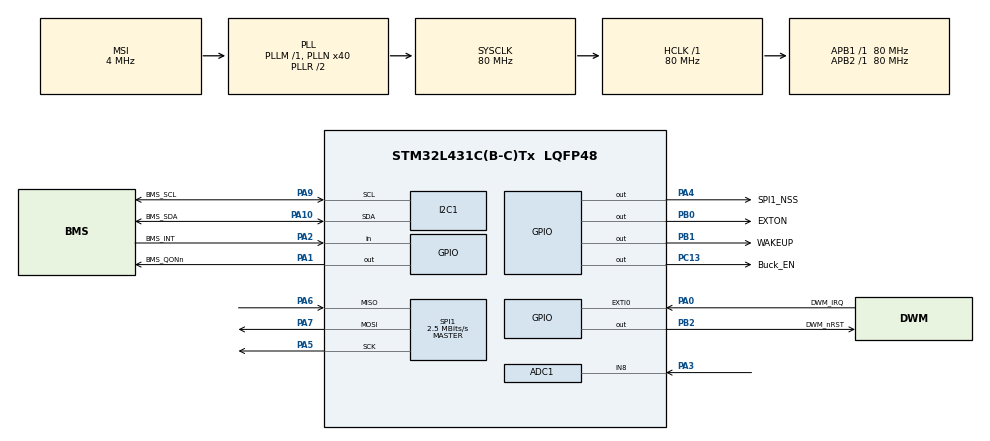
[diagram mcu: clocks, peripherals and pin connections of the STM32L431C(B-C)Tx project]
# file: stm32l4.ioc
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ADC1.Channel-0\#ChannelRegularConversion=ADC_CHANNEL_8
ADC1.NbrOfConversionFlag=1
ADC1.OffsetNumber-0\#ChannelRegularConversion=ADC_OFFSET_NONE
ADC1.Rank-0\#ChannelRegularConversion=1
ADC1.SamplingTime-0\#ChannelRegularConversion=ADC_SAMPLETIME_2CYCLES_5
ADC1.master=1
I2C1.Timing=0x10D19CE4
Mcu.Family=STM32L4
Mcu.Name=STM32L431C(B-C)Tx
Mcu.Package=LQFP48
NVIC.EXTI0_IRQn=true\:0\:0\:false\:false\:true\:true\:true\:true
NVIC.PriorityGroup=NVIC_PRIORITYGROUP_4
PA0.GPIO_Label=DWM_IRQ
PA0.Signal=GPXTI0
PA1.GPIO_Label=BMS_QONn
PA1.Signal=GPIO_Output
PA10.GPIO_Label=BMS_SDA
PA10.Mode=I2C
PA10.Signal=I2C1_SDA
PA13\ (JTMS-SWDIO).Mode=Trace_Asynchronous_SW
PA13\ (JTMS-SWDIO).Signal=SYS_JTMS-SWDIO
PA14\ (JTCK-SWCLK).Mode=Trace_Asynchronous_SW
PA14\ (JTCK-SWCLK).Signal=SYS_JTCK-SWCLK
PA2.GPIO_Label=BMS_INT
PA2.Signal=GPIO_Input
PA3.Signal=ADCx_IN8
PA4.GPIO_Label=SPI1_NSS
PA4.GPIO_PuPd=GPIO_PULLUP
PA4.GPIO_Speed=GPIO_SPEED_FREQ_MEDIUM
PA4.Signal=GPIO_Output
PA5.Mode=Full_Duplex_Master
PA5.Signal=SPI1_SCK
PA6.Mode=Full_Duplex_Master
PA6.Signal=SPI1_MISO
PA7.Mode=Full_Duplex_Master
PA7.Signal=SPI1_MOSI
PA9.GPIO_Label=BMS_SCL
PA9.Mode=I2C
PA9.Signal=I2C1_SCL
PB0.GPIO_Label=EXTON
PB0.Signal=GPIO_Output
PB1.GPIO_Label=WAKEUP
PB1.GPIO_Speed=GPIO_SPEED_FREQ_MEDIUM
PB1.Signal=GPIO_Output
PB2.GPIO_Label=DWM_nRST
PB2.PinState=GPIO_PIN_SET
PB2.Signal=GPIO_Output
PB3\ (JTDO-TRACESWO).Mode=Trace_Asynchronous_SW
PB3\ (JTDO-TRACESWO).Signal=SYS_JTDO-SWO
PC13.GPIO_Label=Buck_EN
PC13.Signal=GPIO_Output
PC14-OSC32_IN\ (PC14).Mode=LSE-External-Oscillator
PC14-OSC32_IN\ (PC14).Signal=RCC_OSC32_IN
PC15-OSC32_OUT\ (PC15).Mode=LSE-External-Oscillator
PC15-OSC32_OUT\ (PC15).Signal=RCC_OSC32_OUT
PH0-OSC_IN\ (PH0).Mode=HSE-External-Oscillator
PH0-OSC_IN\ (PH0).Signal=RCC_OSC_IN
PH1-OSC_OUT\ (PH1).Mode=HSE-External-Oscillator
PH1-OSC_OUT\ (PH1).Signal=RCC_OSC_OUT
ProjectManager.HeapSize=0x200
ProjectManager.StackSize=0x400
ProjectManager.TargetToolchain=CMake
RCC.ADCFreq_Value=32000000
RCC.AHBFreq_Value=80000000
RCC.APB1Freq_Value=80000000
RCC.APB1TimFreq_Value=80000000
RCC.APB2Freq_Value=80000000
RCC.APB2TimFreq_Value=80000000
RCC.CortexFreq_Value=80000000
RCC.HCLKFreq_Value=80000000
RCC.HSE_VALUE=8000000
RCC.HSI48_VALUE=48000000
RCC.HSI_VALUE=16000000
RCC.MSI_VALUE=4000000
RCC.PLLN=40
RCC.PLLSAI1N=16
RCC.SYSCLKFreq_VALUE=80000000
RCC.SYSCLKSource=RCC_SYSCLKSOURCE_PLLCLK
RCC.VCOOutputFreq_Value=160000000
SH.ADCx_IN8.0=ADC1_IN8,IN8-Single-Ended
SPI1.BaudRatePrescaler=SPI_BAUDRATEPRESCALER_32
SPI1.CalculateBaudRate=2.5 MBits/s
SPI1.DataSize=SPI_DATASIZE_8BIT
SPI1.Direction=SPI_DIRECTION_2LINES
SPI1.Mode=SPI_MODE_MASTER
SPI1.VirtualType=VM_MASTER
board=custom

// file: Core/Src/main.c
/* USER CODE BEGIN Header */
/**
 ******************************************************************************
 * @file           : main.c
 * @brief          : Main program body
 ******************************************************************************
 * @attention
 *
 * Copyright (c) 2026 STMicroelectronics.
 * All rights reserved.
 *
 * This software is licensed under terms that can be found in the LICENSE file
 * in the root directory of this software component.
 * If no LICENSE file comes with this software, it is provided AS-IS.
 *
 ******************************************************************************
 */
/* USER CODE END Header */
#include "main.h"

/* USER CODE BEGIN Includes */
#include "communication.h"
#include "deca_device_api.h"
#include "deca_interface.h"
#include "dw3000_config.h"
#include "port.h"
#include <stdint.h>

/* USER CODE END Includes */

ADC_HandleTypeDef hadc1;

I2C_HandleTypeDef hi2c1;

SPI_HandleTypeDef hspi1;

void SystemClock_Config(void);
static void MX_GPIO_Init(void);
static void MX_SPI1_Init(void);
static void MX_ADC1_Init(void);
static void MX_I2C1_Init(void);
/* USER CODE BEGIN PFP */
void init_SPI()
{
    MX_SPI1_Init();
}
/* USER CODE END PFP */

int main(void)
{

    /* MCU Configuration--------------------------------------------------------*/

    /* Reset of all peripherals, Initializes the Flash interface and the Systick. */
    HAL_Init();

    /* Configure the system clock */
    SystemClock_Config();

    /* Initialize all configured peripherals */
    MX_GPIO_Init();
    MX_SPI1_Init();
    MX_ADC1_Init();
    MX_I2C1_Init();
    /* USER CODE BEGIN 2 */
    HAL_GPIO_WritePin(SPI1_NSS_GPIO_Port, SPI1_NSS_Pin, GPIO_PIN_RESET);
    dwm300_initialize();

    /* USER CODE END 2 */

    /* Infinite loop */
    while (1)
    {
        static uint8_t msg[] = {'t', 'e', 's', 't', ' ', 'm', 'e', 's', 's', 'a', 'g', 'e', '!'};
        send_msg_polling(msg);

        HAL_Delay(100000000000);
        static uint8_t rec[sizeof(msg)];
        recieve_msg_polling(rec);
    }
}

void SystemClock_Config(void)
{
    RCC_OscInitTypeDef RCC_OscInitStruct = {0};
    RCC_ClkInitTypeDef RCC_ClkInitStruct = {0};

    /** Configure the main internal regulator output voltage
     */
    if (HAL_PWREx_ControlVoltageScaling(PWR_REGULATOR_VOLTAGE_SCALE1) != HAL_OK)
    {
        Error_Handler();
    }

    /** Configure LSE Drive Capability
     */
    HAL_PWR_EnableBkUpAccess();
    __HAL_RCC_LSEDRIVE_CONFIG(RCC_LSEDRIVE_LOW);

    /** Initializes the RCC Oscillators according to the specified parameters
     * in the RCC_OscInitTypeDef structure.
     */
    RCC_OscInitStruct.OscillatorType = RCC_OSCILLATORTYPE_LSE | RCC_OSCILLATORTYPE_MSI;
    RCC_OscInitStruct.LSEState = RCC_LSE_ON;
    RCC_OscInitStruct.MSIState = RCC_MSI_ON;
    RCC_OscInitStruct.MSICalibrationValue = 0;
    RCC_OscInitStruct.MSIClockRange = RCC_MSIRANGE_6;
    RCC_OscInitStruct.PLL.PLLState = RCC_PLL_ON;
    RCC_OscInitStruct.PLL.PLLSource = RCC_PLLSOURCE_MSI;
    RCC_OscInitStruct.PLL.PLLM = 1;
    RCC_OscInitStruct.PLL.PLLN = 40;
    RCC_OscInitStruct.PLL.PLLP = RCC_PLLP_DIV7;
    RCC_OscInitStruct.PLL.PLLQ = RCC_PLLQ_DIV2;
    RCC_OscInitStruct.PLL.PLLR = RCC_PLLR_DIV2;
    if (HAL_RCC_OscConfig(&RCC_OscInitStruct) != HAL_OK)
    {
        Error_Handler();
    }

    /** Initializes the CPU, AHB and APB buses clocks
     */
    RCC_ClkInitStruct.ClockType = RCC_CLOCKTYPE_HCLK | RCC_CLOCKTYPE_SYSCLK | RCC_CLOCKTYPE_PCLK1 | RCC_CLOCKTYPE_PCLK2;
    RCC_ClkInitStruct.SYSCLKSource = RCC_SYSCLKSOURCE_PLLCLK;
    RCC_ClkInitStruct.AHBCLKDivider = RCC_SYSCLK_DIV1;
    RCC_ClkInitStruct.APB1CLKDivider = RCC_HCLK_DIV1;
    RCC_ClkInitStruct.APB2CLKDivider = RCC_HCLK_DIV1;

    if (HAL_RCC_ClockConfig(&RCC_ClkInitStruct, FLASH_LATENCY_4) != HAL_OK)
    {
        Error_Handler();
    }

    /** Enable MSI Auto calibration
     */
    HAL_RCCEx_EnableMSIPLLMode();
}

static void MX_ADC1_Init(void)
{

    ADC_ChannelConfTypeDef sConfig = {0};

    /** Common config
     */
    hadc1.Instance = ADC1;
    hadc1.Init.ClockPrescaler = ADC_CLOCK_ASYNC_DIV1;
    hadc1.Init.Resolution = ADC_RESOLUTION_12B;
    hadc1.Init.DataAlign = ADC_DATAALIGN_RIGHT;
    hadc1.Init.ScanConvMode = ADC_SCAN_DISABLE;
    hadc1.Init.EOCSelection = ADC_EOC_SINGLE_CONV;
    hadc1.Init.LowPowerAutoWait = DISABLE;
    hadc1.Init.ContinuousConvMode = DISABLE;
    hadc1.Init.NbrOfConversion = 1;
    hadc1.Init.DiscontinuousConvMode = DISABLE;
    hadc1.Init.ExternalTrigConv = ADC_SOFTWARE_START;
    hadc1.Init.ExternalTrigConvEdge = ADC_EXTERNALTRIGCONVEDGE_NONE;
    hadc1.Init.DMAContinuousRequests = DISABLE;
    hadc1.Init.Overrun = ADC_OVR_DATA_PRESERVED;
    hadc1.Init.OversamplingMode = DISABLE;
    if (HAL_ADC_Init(&hadc1) != HAL_OK)
    {
        Error_Handler();
    }

    /** Configure Regular Channel
     */
    sConfig.Channel = ADC_CHANNEL_8;
    sConfig.Rank = ADC_REGULAR_RANK_1;
    sConfig.SamplingTime = ADC_SAMPLETIME_2CYCLES_5;
    sConfig.SingleDiff = ADC_SINGLE_ENDED;
    sConfig.OffsetNumber = ADC_OFFSET_NONE;
    sConfig.Offset = 0;
    if (HAL_ADC_ConfigChannel(&hadc1, &sConfig) != HAL_OK)
    {
        Error_Handler();
    }
}

static void MX_I2C1_Init(void)
{

    hi2c1.Instance = I2C1;
    hi2c1.Init.Timing = 0x10D19CE4;
    hi2c1.Init.OwnAddress1 = 0;
    hi2c1.Init.AddressingMode = I2C_ADDRESSINGMODE_7BIT;
    hi2c1.Init.DualAddressMode = I2C_DUALADDRESS_DISABLE;
    hi2c1.Init.OwnAddress2 = 0;
    hi2c1.Init.OwnAddress2Masks = I2C_OA2_NOMASK;
    hi2c1.Init.GeneralCallMode = I2C_GENERALCALL_DISABLE;
    hi2c1.Init.NoStretchMode = I2C_NOSTRETCH_DISABLE;
    if (HAL_I2C_Init(&hi2c1) != HAL_OK)
    {
        Error_Handler();
    }

    /** Configure Analogue filter
     */
    if (HAL_I2CEx_ConfigAnalogFilter(&hi2c1, I2C_ANALOGFILTER_ENABLE) != HAL_OK)
    {
        Error_Handler();
    }

    /** Configure Digital filter
     */
    if (HAL_I2CEx_ConfigDigitalFilter(&hi2c1, 0) != HAL_OK)
    {
        Error_Handler();
    }
}

static void MX_SPI1_Init(void)
{

    /* SPI1 parameter configuration*/
    hspi1.Instance = SPI1;
    hspi1.Init.Mode = SPI_MODE_MASTER;
    hspi1.Init.Direction = SPI_DIRECTION_2LINES;
    hspi1.Init.DataSize = SPI_DATASIZE_8BIT;
    hspi1.Init.CLKPolarity = SPI_POLARITY_LOW;
    hspi1.Init.CLKPhase = SPI_PHASE_1EDGE;
    hspi1.Init.NSS = SPI_NSS_SOFT;
    hspi1.Init.BaudRatePrescaler = SPI_BAUDRATEPRESCALER_32;
    hspi1.Init.FirstBit = SPI_FIRSTBIT_MSB;
    hspi1.Init.TIMode = SPI_TIMODE_DISABLE;
    hspi1.Init.CRCCalculation = SPI_CRCCALCULATION_DISABLE;
    hspi1.Init.CRCPolynomial = 7;
    hspi1.Init.CRCLength = SPI_CRC_LENGTH_DATASIZE;
    hspi1.Init.NSSPMode = SPI_NSS_PULSE_ENABLE;
    if (HAL_SPI_Init(&hspi1) != HAL_OK)
    {
        Error_Handler();
    }
}

static void MX_GPIO_Init(void)
{
    GPIO_InitTypeDef GPIO_InitStruct = {0};

    /* GPIO Ports Clock Enable */
    __HAL_RCC_GPIOC_CLK_ENABLE();
    __HAL_RCC_GPIOH_CLK_ENABLE();
    __HAL_RCC_GPIOA_CLK_ENABLE();
    __HAL_RCC_GPIOB_CLK_ENABLE();

    /*Configure GPIO pin Output Level */
    HAL_GPIO_WritePin(Buck_EN_GPIO_Port, Buck_EN_Pin, GPIO_PIN_RESET);

    /*Configure GPIO pin Output Level */
    HAL_GPIO_WritePin(GPIOA, BMS_QONn_Pin | SPI1_NSS_Pin, GPIO_PIN_RESET);

    /*Configure GPIO pin Output Level */
    HAL_GPIO_WritePin(GPIOB, EXTON_Pin | WAKEUP_Pin, GPIO_PIN_RESET);

    /*Configure GPIO pin Output Level */
    HAL_GPIO_WritePin(DWM_nRST_GPIO_Port, DWM_nRST_Pin, GPIO_PIN_SET);

    /*Configure GPIO pin : Buck_EN_Pin */
    GPIO_InitStruct.Pin = Buck_EN_Pin;
    GPIO_InitStruct.Mode = GPIO_MODE_OUTPUT_PP;
    GPIO_InitStruct.Pull = GPIO_NOPULL;
    GPIO_InitStruct.Speed = GPIO_SPEED_FREQ_LOW;
    HAL_GPIO_Init(Buck_EN_GPIO_Port, &GPIO_InitStruct);

    /*Configure GPIO pin : DWM_IRQ_Pin */
    GPIO_InitStruct.Pin = DWM_IRQ_Pin;
    GPIO_InitStruct.Mode = GPIO_MODE_IT_RISING;
    GPIO_InitStruct.Pull = GPIO_NOPULL;
    HAL_GPIO_Init(DWM_IRQ_GPIO_Port, &GPIO_InitStruct);

    /*Configure GPIO pin : BMS_QONn_Pin */
    GPIO_InitStruct.Pin = BMS_QONn_Pin;
    GPIO_InitStruct.Mode = GPIO_MODE_OUTPUT_PP;
    GPIO_InitStruct.Pull = GPIO_NOPULL;
    GPIO_InitStruct.Speed = GPIO_SPEED_FREQ_LOW;
    HAL_GPIO_Init(BMS_QONn_GPIO_Port, &GPIO_InitStruct);

    /*Configure GPIO pin : BMS_INT_Pin */
    GPIO_InitStruct.Pin = BMS_INT_Pin;
    GPIO_InitStruct.Mode = GPIO_MODE_INPUT;
    GPIO_InitStruct.Pull = GPIO_NOPULL;
    HAL_GPIO_Init(BMS_INT_GPIO_Port, &GPIO_InitStruct);

    /*Configure GPIO pin : SPI1_NSS_Pin */
    GPIO_InitStruct.Pin = SPI1_NSS_Pin;
    GPIO_InitStruct.Mode = GPIO_MODE_OUTPUT_PP;
    GPIO_InitStruct.Pull = GPIO_PULLUP;
    GPIO_InitStruct.Speed = GPIO_SPEED_FREQ_MEDIUM;
    HAL_GPIO_Init(SPI1_NSS_GPIO_Port, &GPIO_InitStruct);

    /*Configure GPIO pins : EXTON_Pin DWM_nRST_Pin */
    GPIO_InitStruct.Pin = EXTON_Pin | DWM_nRST_Pin;
    GPIO_InitStruct.Mode = GPIO_MODE_OUTPUT_PP;
    GPIO_InitStruct.Pull = GPIO_NOPULL;
    GPIO_InitStruct.Speed = GPIO_SPEED_FREQ_LOW;
    HAL_GPIO_Init(GPIOB, &GPIO_InitStruct);

    /*Configure GPIO pin : WAKEUP_Pin */
    GPIO_InitStruct.Pin = WAKEUP_Pin;
    GPIO_InitStruct.Mode = GPIO_MODE_OUTPUT_PP;
    GPIO_InitStruct.Pull = GPIO_NOPULL;
    GPIO_InitStruct.Speed = GPIO_SPEED_FREQ_MEDIUM;
    HAL_GPIO_Init(WAKEUP_GPIO_Port, &GPIO_InitStruct);

    /* EXTI interrupt init*/
    HAL_NVIC_SetPriority(EXTI0_IRQn, 0, 0);
    HAL_NVIC_EnableIRQ(EXTI0_IRQn);

}

void Error_Handler(void)
{
    __disable_irq();
    while (1)
    {
    }
}
